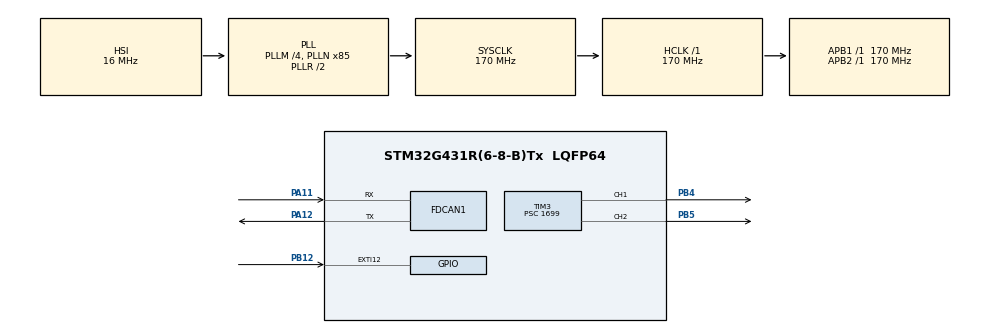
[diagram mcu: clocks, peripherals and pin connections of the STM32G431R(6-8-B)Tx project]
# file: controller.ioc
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FDCAN1.CalculateBaudRateNominal=3541666
FDCAN1.CalculateTimeBitNominal=282
FDCAN1.CalculateTimeQuantumNominal=94.11764705882354
FDCAN1.FrameFormat=FDCAN_FRAME_FD_NO_BRS
Mcu.Family=STM32G4
Mcu.Name=STM32G431R(6-8-B)Tx
Mcu.Package=LQFP64
NVIC.EXTI15_10_IRQn=true\:0\:0\:false\:false\:true\:true\:true\:true
NVIC.FDCAN1_IT0_IRQn=true\:0\:0\:false\:false\:true\:true\:true\:true
NVIC.FDCAN1_IT1_IRQn=true\:0\:0\:false\:false\:true\:true\:true\:true
NVIC.PriorityGroup=NVIC_PRIORITYGROUP_4
PA11.Mode=FDCAN_Activate
PA11.Signal=FDCAN1_RX
PA12.Mode=FDCAN_Activate
PA12.Signal=FDCAN1_TX
PB12.GPIO_PuPd=GPIO_PULLDOWN
PB12.Signal=GPXTI12
PB4.Signal=S_TIM3_CH1
PB5.Signal=S_TIM3_CH2
ProjectManager.HeapSize=0x200
ProjectManager.StackSize=0x400
ProjectManager.TargetToolchain=STM32CubeIDE
RCC.ADC12Freq_Value=170000000
RCC.AHBFreq_Value=170000000
RCC.APB1Freq_Value=170000000
RCC.APB1TimFreq_Value=170000000
RCC.APB2Freq_Value=170000000
RCC.APB2TimFreq_Value=170000000
RCC.CortexFreq_Value=170000000
RCC.EXTERNAL_CLOCK_VALUE=12288000
RCC.HCLKFreq_Value=170000000
RCC.HSE_VALUE=8000000
RCC.HSI48_VALUE=48000000
RCC.HSI_VALUE=16000000
RCC.LSE_VALUE=32768
RCC.PLLM=RCC_PLLM_DIV4
RCC.PLLN=85
RCC.SYSCLKFreq_VALUE=170000000
RCC.SYSCLKSource=RCC_SYSCLKSOURCE_PLLCLK
RCC.USBFreq_Value=170000000
RCC.VCOOutputFreq_Value=340000000
SH.S_TIM3_CH1.0=TIM3_CH1,PWM Generation1 CH1
SH.S_TIM3_CH2.0=TIM3_CH2,PWM Generation2 CH2
TIM3.Channel-PWM\ Generation1\ CH1=TIM_CHANNEL_1
TIM3.Channel-PWM\ Generation2\ CH2=TIM_CHANNEL_2
TIM3.PeriodNoDither=1999
TIM3.Prescaler=1699
VP_SYS_VS_DBSignals.Mode=DisableDeadBatterySignals
board=custom

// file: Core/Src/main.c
/* USER CODE BEGIN Header */
/**
  ******************************************************************************
  * @file           : main.c
  * @brief          : Main program body
  ******************************************************************************
  * @attention
  *
  * Copyright (c) 2026 STMicroelectronics.
  * All rights reserved.
  *
  * This software is licensed under terms that can be found in the LICENSE file
  * in the root directory of this software component.
  * If no LICENSE file comes with this software, it is provided AS-IS.
  *
  ******************************************************************************
  */
/* USER CODE END Header */
#include "main.h"

/* USER CODE BEGIN Includes */
#include "../../../libs/main_orchestrator_controller/main_orchestrator_controller.h"
/* USER CODE END Includes */

FDCAN_HandleTypeDef hfdcan1;

TIM_HandleTypeDef htim3;

void SystemClock_Config(void);
static void MX_GPIO_Init(void);
static void MX_FDCAN1_Init(void);
static void MX_TIM3_Init(void);

int main(void)
{

  /* MCU Configuration--------------------------------------------------------*/

  /* Reset of all peripherals, Initializes the Flash interface and the Systick. */
  HAL_Init();

  /* Configure the system clock */
  SystemClock_Config();

  /* Initialize all configured peripherals */
  MX_GPIO_Init();
  MX_FDCAN1_Init();
  MX_TIM3_Init();
  /* USER CODE BEGIN 2 */
  initialize_controller(&hfdcan1, &htim3);
  /* USER CODE END 2 */

  /* Infinite loop */
  /* USER CODE BEGIN WHILE */
  while (1)
  {
	main_loop_controller();
    /* USER CODE END WHILE */

  }
}

void SystemClock_Config(void)
{
  RCC_OscInitTypeDef RCC_OscInitStruct = {0};
  RCC_ClkInitTypeDef RCC_ClkInitStruct = {0};

  /** Configure the main internal regulator output voltage
  */
  HAL_PWREx_ControlVoltageScaling(PWR_REGULATOR_VOLTAGE_SCALE1_BOOST);

  /** Initializes the RCC Oscillators according to the specified parameters
  * in the RCC_OscInitTypeDef structure.
  */
  RCC_OscInitStruct.OscillatorType = RCC_OSCILLATORTYPE_HSI;
  RCC_OscInitStruct.HSIState = RCC_HSI_ON;
  RCC_OscInitStruct.HSICalibrationValue = RCC_HSICALIBRATION_DEFAULT;
  RCC_OscInitStruct.PLL.PLLState = RCC_PLL_ON;
  RCC_OscInitStruct.PLL.PLLSource = RCC_PLLSOURCE_HSI;
  RCC_OscInitStruct.PLL.PLLM = RCC_PLLM_DIV4;
  RCC_OscInitStruct.PLL.PLLN = 85;
  RCC_OscInitStruct.PLL.PLLP = RCC_PLLP_DIV2;
  RCC_OscInitStruct.PLL.PLLQ = RCC_PLLQ_DIV2;
  RCC_OscInitStruct.PLL.PLLR = RCC_PLLR_DIV2;
  if (HAL_RCC_OscConfig(&RCC_OscInitStruct) != HAL_OK)
  {
    Error_Handler();
  }

  /** Initializes the CPU, AHB and APB buses clocks
  */
  RCC_ClkInitStruct.ClockType = RCC_CLOCKTYPE_HCLK|RCC_CLOCKTYPE_SYSCLK
                              |RCC_CLOCKTYPE_PCLK1|RCC_CLOCKTYPE_PCLK2;
  RCC_ClkInitStruct.SYSCLKSource = RCC_SYSCLKSOURCE_PLLCLK;
  RCC_ClkInitStruct.AHBCLKDivider = RCC_SYSCLK_DIV1;
  RCC_ClkInitStruct.APB1CLKDivider = RCC_HCLK_DIV1;
  RCC_ClkInitStruct.APB2CLKDivider = RCC_HCLK_DIV1;

  if (HAL_RCC_ClockConfig(&RCC_ClkInitStruct, FLASH_LATENCY_4) != HAL_OK)
  {
    Error_Handler();
  }
}

static void MX_FDCAN1_Init(void)
{

  hfdcan1.Instance = FDCAN1;
  hfdcan1.Init.ClockDivider = FDCAN_CLOCK_DIV1;
  hfdcan1.Init.FrameFormat = FDCAN_FRAME_FD_NO_BRS;
  hfdcan1.Init.Mode = FDCAN_MODE_NORMAL;
  hfdcan1.Init.AutoRetransmission = DISABLE;
  hfdcan1.Init.TransmitPause = DISABLE;
  hfdcan1.Init.ProtocolException = DISABLE;
  hfdcan1.Init.NominalPrescaler = 16;
  hfdcan1.Init.NominalSyncJumpWidth = 1;
  hfdcan1.Init.NominalTimeSeg1 = 1;
  hfdcan1.Init.NominalTimeSeg2 = 1;
  hfdcan1.Init.DataPrescaler = 1;
  hfdcan1.Init.DataSyncJumpWidth = 1;
  hfdcan1.Init.DataTimeSeg1 = 1;
  hfdcan1.Init.DataTimeSeg2 = 1;
  hfdcan1.Init.StdFiltersNbr = 0;
  hfdcan1.Init.ExtFiltersNbr = 0;
  hfdcan1.Init.TxFifoQueueMode = FDCAN_TX_FIFO_OPERATION;
  if (HAL_FDCAN_Init(&hfdcan1) != HAL_OK)
  {
    Error_Handler();
  }

}

static void MX_TIM3_Init(void)
{

  TIM_MasterConfigTypeDef sMasterConfig = {0};
  TIM_OC_InitTypeDef sConfigOC = {0};

  htim3.Instance = TIM3;
  htim3.Init.Prescaler = 1699;
  htim3.Init.CounterMode = TIM_COUNTERMODE_UP;
  htim3.Init.Period = 1999;
  htim3.Init.ClockDivision = TIM_CLOCKDIVISION_DIV1;
  htim3.Init.AutoReloadPreload = TIM_AUTORELOAD_PRELOAD_DISABLE;
  if (HAL_TIM_PWM_Init(&htim3) != HAL_OK)
  {
    Error_Handler();
  }
  sMasterConfig.MasterOutputTrigger = TIM_TRGO_RESET;
  sMasterConfig.MasterSlaveMode = TIM_MASTERSLAVEMODE_DISABLE;
  if (HAL_TIMEx_MasterConfigSynchronization(&htim3, &sMasterConfig) != HAL_OK)
  {
    Error_Handler();
  }
  sConfigOC.OCMode = TIM_OCMODE_PWM1;
  sConfigOC.Pulse = 0;
  sConfigOC.OCPolarity = TIM_OCPOLARITY_HIGH;
  sConfigOC.OCFastMode = TIM_OCFAST_DISABLE;
  if (HAL_TIM_PWM_ConfigChannel(&htim3, &sConfigOC, TIM_CHANNEL_1) != HAL_OK)
  {
    Error_Handler();
  }
  if (HAL_TIM_PWM_ConfigChannel(&htim3, &sConfigOC, TIM_CHANNEL_2) != HAL_OK)
  {
    Error_Handler();
  }
  HAL_TIM_MspPostInit(&htim3);

}

static void MX_GPIO_Init(void)
{
  GPIO_InitTypeDef GPIO_InitStruct = {0};

  /* GPIO Ports Clock Enable */
  __HAL_RCC_GPIOB_CLK_ENABLE();
  __HAL_RCC_GPIOA_CLK_ENABLE();

  /*Configure GPIO pin : PB12 */
  GPIO_InitStruct.Pin = GPIO_PIN_12;
  GPIO_InitStruct.Mode = GPIO_MODE_IT_RISING;
  GPIO_InitStruct.Pull = GPIO_PULLDOWN;
  HAL_GPIO_Init(GPIOB, &GPIO_InitStruct);

  /* EXTI interrupt init*/
  HAL_NVIC_SetPriority(EXTI15_10_IRQn, 0, 0);
  HAL_NVIC_EnableIRQ(EXTI15_10_IRQn);

}

void Error_Handler(void)
{
  __disable_irq();
  while (1)
  {
  }
}
